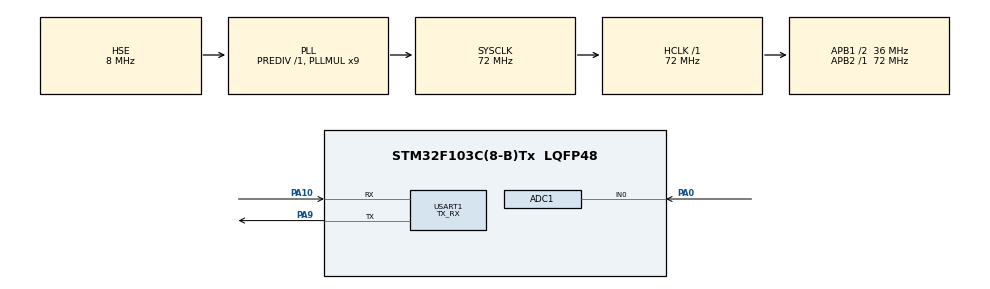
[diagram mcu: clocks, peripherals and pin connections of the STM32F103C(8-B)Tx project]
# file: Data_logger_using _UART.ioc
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ADC1.Channel-0\#ChannelRegularConversion=ADC_CHANNEL_0
ADC1.NbrOfConversion=1
ADC1.NbrOfConversionFlag=1
ADC1.Rank-0\#ChannelRegularConversion=1
ADC1.SamplingTime-0\#ChannelRegularConversion=ADC_SAMPLETIME_1CYCLE_5
ADC1.master=1
Mcu.Family=STM32F1
Mcu.Name=STM32F103C(8-B)Tx
Mcu.Package=LQFP48
NVIC.ADC1_2_IRQn=true\:0\:0\:false\:false\:true\:true\:true\:true
NVIC.PriorityGroup=NVIC_PRIORITYGROUP_4
NVIC.TIM2_IRQn=true\:0\:0\:false\:false\:true\:true\:true\:true
NVIC.USART1_IRQn=true\:0\:0\:false\:false\:true\:true\:true\:true
PA0-WKUP.Signal=ADCx_IN0
PA10.Mode=Asynchronous
PA10.Signal=USART1_RX
PA9.Mode=Asynchronous
PA9.Signal=USART1_TX
PD0-OSC_IN.Mode=HSE-External-Oscillator
PD0-OSC_IN.Signal=RCC_OSC_IN
PD1-OSC_OUT.Mode=HSE-External-Oscillator
PD1-OSC_OUT.Signal=RCC_OSC_OUT
ProjectManager.HeapSize=0x200
ProjectManager.StackSize=0x400
ProjectManager.TargetToolchain=STM32CubeIDE
RCC.ADCPresc=RCC_ADCPCLK2_DIV6
RCC.AHBFreq_Value=72000000
RCC.APB1CLKDivider=RCC_HCLK_DIV2
RCC.APB1Freq_Value=36000000
RCC.APB1TimFreq_Value=72000000
RCC.APB2Freq_Value=72000000
RCC.APB2TimFreq_Value=72000000
RCC.HCLKFreq_Value=72000000
RCC.PLLMUL=RCC_PLL_MUL9
RCC.PLLSourceVirtual=RCC_PLLSOURCE_HSE
RCC.SYSCLKFreq_VALUE=72000000
RCC.SYSCLKSource=RCC_SYSCLKSOURCE_PLLCLK
RCC.USBFreq_Value=72000000
SH.ADCx_IN0.0=ADC1_IN0,IN0
TIM2.Period=1999
TIM2.Prescaler=7199
USART1.Mode=MODE_TX_RX
USART1.VirtualMode=VM_ASYNC
VP_SYS_VS_ND.Mode=No_Debug
VP_TIM2_VS_ClockSourceINT.Mode=Internal
board=custom

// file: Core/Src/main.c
/* USER CODE BEGIN Header */
/**
  ******************************************************************************
  * @file           : main.c
  * @brief          : Main program body
  ******************************************************************************
  * @attention
  *
  * Copyright (c) 2026 STMicroelectronics.
  * All rights reserved.
  *
  * This software is licensed under terms that can be found in the LICENSE file
  * in the root directory of this software component.
  * If no LICENSE file comes with this software, it is provided AS-IS.
  *
  ******************************************************************************
  */
/* USER CODE END Header */
#include "main.h"

ADC_HandleTypeDef hadc1;

TIM_HandleTypeDef htim2;

UART_HandleTypeDef huart1;

void SystemClock_Config(void);
static void MX_GPIO_Init(void);
static void MX_ADC1_Init(void);
static void MX_USART1_UART_Init(void);
static void MX_TIM2_Init(void);
static void ASCII_conversion(char *val,uint16_t ADC_value,uint16_t timestamp);

/* USER CODE BEGIN 0 */

volatile uint16_t ADC_value =0;
volatile uint8_t ADC_flag=0;
volatile uint8_t UART_flag=1;
volatile uint16_t timestamp=0;

char val[11];

// ADC completion callback
void HAL_ADC_ConvCpltCallback(ADC_HandleTypeDef* hadc)
{
	ADC_value = HAL_ADC_GetValue(&hadc1);
	ADC_flag = 1;

}

void HAL_TIM_PeriodElapsedCallback(TIM_HandleTypeDef* htim)
{
	 timestamp+=20;
	 HAL_ADC_Start_IT(&hadc1);
}

// UART transmission completion callback
void HAL_UART_TxCpltCallback(UART_HandleTypeDef *huart)
{
//	HAL_ADC_Start_IT(&hadc1);
	UART_flag = 1;
}
/* USER CODE END 0 */

int main(void)
{

  /* MCU Configuration--------------------------------------------------------*/

  /* Reset of all peripherals, Initializes the Flash interface and the Systick. */
  HAL_Init();

  /* Configure the system clock */
  SystemClock_Config();

  /* Initialize all configured peripherals */
  MX_GPIO_Init();
  MX_ADC1_Init();
  MX_USART1_UART_Init();
  MX_TIM2_Init();
  /* USER CODE BEGIN 2 */

  HAL_TIM_Base_Start_IT(&htim2);

  /* USER CODE END 2 */

  /* Infinite loop */
  while (1)
  {
	 if(ADC_flag && UART_flag)
	 {
		 ADC_flag=0;
		 UART_flag=0;
		 ASCII_conversion(val,ADC_value,timestamp); //converts each byte of ADC value into ASCII character
		 HAL_UART_Transmit_IT(&huart1,(uint8_t*) val,sizeof(val));
	 }

  }
}

static void ASCII_conversion(char *val,uint16_t ADC_value,uint16_t timestamp)
{
	val[0] = (timestamp / 1000) % 10 + '0';
	val[1] = (timestamp / 100)  % 10 + '0';
	val[2] = (timestamp / 10)   % 10 + '0';
	val[3] = (timestamp % 10) + '0';
	val[4] = ',';
	val[5] = (ADC_value / 1000) % 10 + '0';
	val[6] = (ADC_value / 100)  % 10 + '0';
	val[7] = (ADC_value / 10)   % 10 + '0';
	val[8] = (ADC_value % 10) + '0';
	val[9] = '\r';
	val[10] = '\n';
}
void SystemClock_Config(void)
{
  RCC_OscInitTypeDef RCC_OscInitStruct = {0};
  RCC_ClkInitTypeDef RCC_ClkInitStruct = {0};
  RCC_PeriphCLKInitTypeDef PeriphClkInit = {0};

  /** Initializes the RCC Oscillators according to the specified parameters
  * in the RCC_OscInitTypeDef structure.
  */
  RCC_OscInitStruct.OscillatorType = RCC_OSCILLATORTYPE_HSE;
  RCC_OscInitStruct.HSEState = RCC_HSE_ON;
  RCC_OscInitStruct.HSEPredivValue = RCC_HSE_PREDIV_DIV1;
  RCC_OscInitStruct.HSIState = RCC_HSI_ON;
  RCC_OscInitStruct.PLL.PLLState = RCC_PLL_ON;
  RCC_OscInitStruct.PLL.PLLSource = RCC_PLLSOURCE_HSE;
  RCC_OscInitStruct.PLL.PLLMUL = RCC_PLL_MUL9;
  if (HAL_RCC_OscConfig(&RCC_OscInitStruct) != HAL_OK)
  {
    Error_Handler();
  }

  /** Initializes the CPU, AHB and APB buses clocks
  */
  RCC_ClkInitStruct.ClockType = RCC_CLOCKTYPE_HCLK|RCC_CLOCKTYPE_SYSCLK
                              |RCC_CLOCKTYPE_PCLK1|RCC_CLOCKTYPE_PCLK2;
  RCC_ClkInitStruct.SYSCLKSource = RCC_SYSCLKSOURCE_PLLCLK;
  RCC_ClkInitStruct.AHBCLKDivider = RCC_SYSCLK_DIV1;
  RCC_ClkInitStruct.APB1CLKDivider = RCC_HCLK_DIV2;
  RCC_ClkInitStruct.APB2CLKDivider = RCC_HCLK_DIV1;

  if (HAL_RCC_ClockConfig(&RCC_ClkInitStruct, FLASH_LATENCY_2) != HAL_OK)
  {
    Error_Handler();
  }
  PeriphClkInit.PeriphClockSelection = RCC_PERIPHCLK_ADC;
  PeriphClkInit.AdcClockSelection = RCC_ADCPCLK2_DIV8;
  if (HAL_RCCEx_PeriphCLKConfig(&PeriphClkInit) != HAL_OK)
  {
    Error_Handler();
  }
}

static void MX_ADC1_Init(void)
{

  ADC_ChannelConfTypeDef sConfig = {0};

  /** Common config
  */
  hadc1.Instance = ADC1;
  hadc1.Init.ScanConvMode = ADC_SCAN_DISABLE;
  hadc1.Init.ContinuousConvMode = DISABLE;
  hadc1.Init.DiscontinuousConvMode = DISABLE;
  hadc1.Init.ExternalTrigConv = ADC_SOFTWARE_START;
  hadc1.Init.DataAlign = ADC_DATAALIGN_RIGHT;
  hadc1.Init.NbrOfConversion = 1;
  if (HAL_ADC_Init(&hadc1) != HAL_OK)
  {
    Error_Handler();
  }

  /** Configure Regular Channel
  */
  sConfig.Channel = ADC_CHANNEL_0;
  sConfig.Rank = ADC_REGULAR_RANK_1;
  sConfig.SamplingTime = ADC_SAMPLETIME_28CYCLES_5;
  if (HAL_ADC_ConfigChannel(&hadc1, &sConfig) != HAL_OK)
  {
    Error_Handler();
  }

}

static void MX_TIM2_Init(void)
{

  TIM_ClockConfigTypeDef sClockSourceConfig = {0};
  TIM_MasterConfigTypeDef sMasterConfig = {0};

  htim2.Instance = TIM2;
  htim2.Init.Prescaler = 7199;
  htim2.Init.CounterMode = TIM_COUNTERMODE_UP;
  htim2.Init.Period = 199;
  htim2.Init.ClockDivision = TIM_CLOCKDIVISION_DIV1;
  htim2.Init.AutoReloadPreload = TIM_AUTORELOAD_PRELOAD_DISABLE;
  if (HAL_TIM_Base_Init(&htim2) != HAL_OK)
  {
    Error_Handler();
  }
  sClockSourceConfig.ClockSource = TIM_CLOCKSOURCE_INTERNAL;
  if (HAL_TIM_ConfigClockSource(&htim2, &sClockSourceConfig) != HAL_OK)
  {
    Error_Handler();
  }
  sMasterConfig.MasterOutputTrigger = TIM_TRGO_RESET;
  sMasterConfig.MasterSlaveMode = TIM_MASTERSLAVEMODE_DISABLE;
  if (HAL_TIMEx_MasterConfigSynchronization(&htim2, &sMasterConfig) != HAL_OK)
  {
    Error_Handler();
  }

}

static void MX_USART1_UART_Init(void)
{

  huart1.Instance = USART1;
  huart1.Init.BaudRate = 9600;
  huart1.Init.WordLength = UART_WORDLENGTH_8B;
  huart1.Init.StopBits = UART_STOPBITS_1;
  huart1.Init.Parity = UART_PARITY_NONE;
  huart1.Init.Mode = UART_MODE_TX_RX;
  huart1.Init.HwFlowCtl = UART_HWCONTROL_NONE;
  huart1.Init.OverSampling = UART_OVERSAMPLING_16;
  if (HAL_UART_Init(&huart1) != HAL_OK)
  {
    Error_Handler();
  }

}

static void MX_GPIO_Init(void)
{

  /* GPIO Ports Clock Enable */
  __HAL_RCC_GPIOD_CLK_ENABLE();
  __HAL_RCC_GPIOA_CLK_ENABLE();

}

void Error_Handler(void)
{
  __disable_irq();
  while (1)
  {
  }
}
